# STM32WB07 register map
File version: 0.4
CPU: CM0+ r0p0, little endian, MPU, no FPU, 2 interrupt priority bits
Registers are 32-bit, read-write, reset 0x0 unless marked. A register's access mark holds for its fields unless they carry their own. Offsets are from the block's base; [hi:lo] are bit positions; {n}, {i} and the like mark numbered series.

## GPIOB
Base 0x48100000
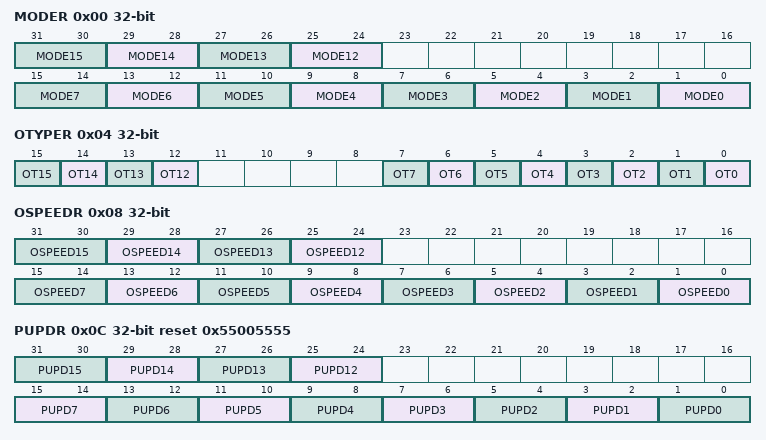
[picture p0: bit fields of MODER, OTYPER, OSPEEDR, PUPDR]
0x00 MODER
  [2n+1:2n] MODE{n} (n=12..15) — MODE{n}[1:0]Port B configuration bits. These bits are written by software to configure the I/O mode. -00: Input mode -01: output mode -10: Alternate function mode -11: Analog mode
  [2n+1:2n] MODE{n} (n=0..7) — MODE{n}[1:0]Port B configuration bits. These bits are written by software to configure the I/O mode. -00: Input mode -01: output mode -10: Alternate function mode -11: Analog mode
0x04 OTYPER
  [n] OT{n} (n=12..15) — OT{n}: Port B configuration bits These bits are written by software to configure the I/O output type. -0: Output push-pull (reset state) -1: Output open-drain
  [n] OT{n} (n=0..7) — OT{n}: Port B configuration bits These bits are written by software to configure the I/O output type. -0: Output push-pull (reset state) -1: Output open-drain
0x08 OSPEEDR
  [2n+1:2n] OSPEED{n} (n=12..15) — OSPEED{n}[1:0]: Port B configuration bits These bits are written by software to configure the I/O output speed.
  [2n+1:2n] OSPEED{n} (n=0..7) — OSPEED{n}[1:0]: Port B configuration bits These bits are written by software to configure the I/O output speed.
0x0C PUPDR reset 0x55005555
  [2n+1:2n] PUPD{n} (n=12..15) — PUPD{n}: Port B configuration bits These bits are written by software to configure the I/O pull-up or pull-down -00: No pull-up, pull-down -01: Pull-up -10: Pull-down -11: Reserved
  [2n+1:2n] PUPD{n} (n=3..7) — PUPD{n}: Port B configuration bits These bits are written by software to configure the I/O pull-up or pull-down -00: No pull-up, pull-down -01: Pull-up -10: Pull-down -11: Reserved
  [5:4] PUPD2 — PUPD2: Port B configuration bits These bits are written by software to configure the I/O pullup or pulldown 00: No pullup, pulldown 01: Pullup 10: Pulldown 11: Reserved
  [3:2] PUPD1 — PUPD1: Port B configuration bits These bits are written by software to configure the I/O pull-up or pull-down 00: No pullup, pulldown 01: Pullup 10: Pulldown 11: Reserved
  [1:0] PUPD0 — PUPD0: Port B configuration bits These bits are written by software to configure the I/O pull-up or pull-down -00: No pull-up, pull-down -01: Pull-up -10: Pull-down -11: Reserved
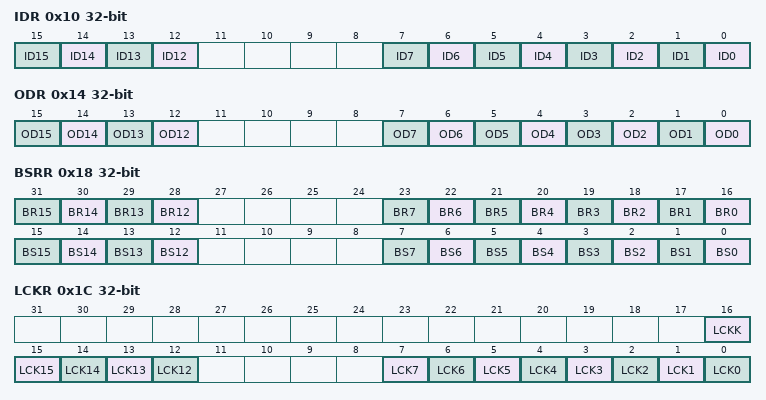
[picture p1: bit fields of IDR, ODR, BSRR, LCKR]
0x10 IDR ro
  [n] ID{n} (n=12..15) — ID{n}: Port B input data bit.These bits are read-only. They contain the input value of the corresponding I/O port
  [n] ID{n} (n=0..7) — ID{n}: Port B input data bit.These bits are read-only. They contain the input value of the corresponding I/O port
0x14 ODR
  [n] OD{n} (n=12..15) — OD{n}: Port B output data bit These bits can be read and written by software
  [n] OD{n} (n=0..7) — OD{n}: Port B output data bit These bits can be read and written by software
0x18 BSRR
  [n+16] BR{n} wo (n=12..15) — BR{n}: Port B reset bit {n} These bits are write-only. A read to these bits returns the value 0x0000. -0: No action on the corresponding ODx bit -1: Resets the corresponding ODx bit Note: If both BSx and BRx are set, BSx has priority
  [n+16] BR{n} wo (n=0..7) — BR{n}: Port B reset bit {n} These bits are write-only. A read to these bits returns the value 0x0000. -0: No action on the corresponding ODx bit -1: Resets the corresponding ODx bit Note: If both BSx and BRx are set, BSx has priority
  [n] BS{n} wo (n=12..15) — BS{n}: Port B set bit {n} These bits are write-only. A read to these bits returns the value 0x0000. -0: No action on the corresponding ODx bit -1: Sets the corresponding ODx bit
  [n] BS{n} wo (n=0..7) — BS{n}: Port B set bit {n} These bits are write-only. A read to these bits returns the value 0x0000. -0: No action on the corresponding ODx bit -1: Sets the corresponding ODx bit
0x1C LCKR
  [16] LCKK — LCKK: Lock key This bit can be read any time. It can only be modified using the lock key write sequence. -0: Port configuration lock key not active -1: Port configuration lock key active. The GPIOx_LCKR register is locked until the next MCU reset or peripheral reset. LOCK key write sequence: WR LCKR[16] = 1 + LCKR[15:0] WR LCKR[16] = 0 + LCKR[15:0] WR LCKR[16] = 1 + LCKR[15:0] RD LCKR RD LCKR[16] = 1 (this read operation is optional but it confirms that the lock is active) Note: During the LOCK key write sequence, the value of LCK[15:0] must not change. Any error in the lock sequence aborts the lock. After the first lock sequence on any bit of the port, any read access on the LCKK bit will return 1 until the next MCU reset or peripheral reset.
  [n] LCK{n} (n=12..15) — LCK{n}: Port B lock bit {n} These bits are read/write but can only be written when the LCKK bit is 0, using the specific sequence described in LCKK bit description. -0: Port configuration not locked -1: Port configuration locked
  [n] LCK{n} (n=0..7) — LCK{n}: Port B lock bit {n} These bits are read/write but can only be written when the LCKK bit is 0, using the specific sequence described in LCKK bit description. -0: Port configuration not locked -1: Port configuration locked
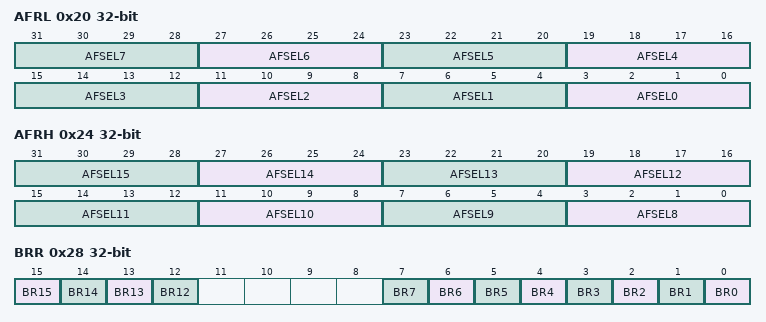
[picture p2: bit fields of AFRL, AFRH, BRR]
0x20 AFRL
  [4n+3:4n] AFSEL{n} (n=0..7) — y[3:0]: Alternate function selection for port B pin y (y = 0..7) These bits are written by software to configure alternate function I/Os AFSELy selection: -0000: AF0 -0001: AF1 -0010: AF2 -0011: AF3 -0100: AF4 -0101: AF5 -0110: AF6 -0111: AF7 1xxx: Reserved
0x24 AFRH
  [4n-29:4n-32] AFSEL{n} (n=8..15) — y[3:0]: Alternate function selection for port B pin y (y = 8..15) These bits are written by software to configure alternate function I/Os AFSELy selection: -0000: AF0 -0001: AF1 -0010: AF2 -0011: AF3 -0100: AF4 -0101: AF5 -0110: AF6 -0111: AF7 1xxx: Reserved
0x28 BRR
  [15] BR15 — BR15: Port B reset bit y (y = 0..15) These bits are write-only. A read to these bits returns the value 0x0000. -0: No action on the corresponding ODx bit -1: Resets the corresponding ODx bit
  [14] BR14 — BR14: Port B reset bit y (y = 0..15) These bits are write-only. A read to these bits returns the value 0x0000. -0: No action on the corresponding ODx bit -1: Resets the corresponding ODx bit
  [13] BR13 — BR13: Port B reset bit y (y = 0..15) These bits are write-only. A read to these bits returns the value 0x0000. -0: No action on the corresponding ODx bit -1: Resets the corresponding ODx bit
  [12] BR12 — BR12 Port B reset bit y (y = 0..15) These bits are write-only. A read to these bits returns the value 0x0000. -0: No action on the corresponding ODx bit -1: Resets the corresponding ODx bit
  [n] BR{n} (n=0..7) — BR{n}: Port B reset bit y (y = 0..15) These bits are write-only. A read to these bits returns the value 0x0000. -0: No action on the corresponding ODx bit -1: Resets the corresponding ODx bit
